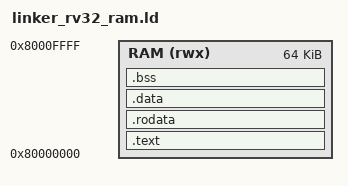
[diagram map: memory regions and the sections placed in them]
/* Linker script for CoreMark on Svarog SoC (RV32, RAM) */

ENTRY(_start)

MEMORY
{
    RAM (rwx) : ORIGIN = 0x80000000, LENGTH = 64K
}

SECTIONS
{
    .text : {
        *(.text.init)
        *(.text*)
    } > RAM

    .rodata : {
        *(.rodata*)
    } > RAM

    .data : {
        __data_start = .;
        *(.data*)
        *(.sdata*)
        __data_end = .;
    } > RAM

    __data_load = __data_start;

    .bss : {
        __bss_start = .;
        *(.bss*)
        *(.sbss*)
        *(COMMON)
        __bss_end = .;
    } > RAM

    _stack_top = ORIGIN(RAM) + LENGTH(RAM);

    /DISCARD/ : {
        *(.comment)
        *(.note*)
        *(.eh_frame*)
    }
}
